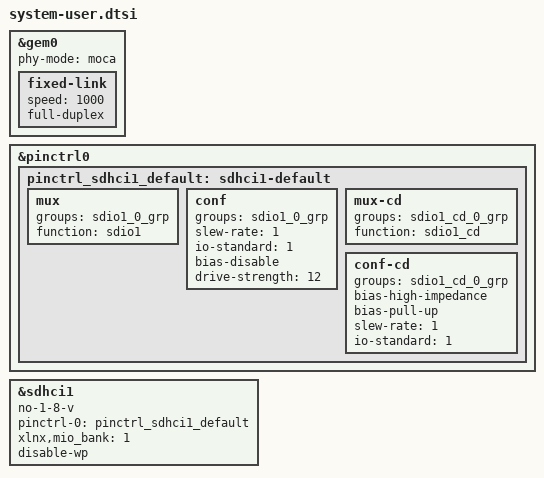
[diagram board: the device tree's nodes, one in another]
/include/ "system-conf.dtsi"
/ {
};




&gem0 {
        phy-mode = "moca";
        fixed-link {
          speed = <1000>;
          full-duplex;
	};
};


&pinctrl0 {
	status = "okay";

      
	pinctrl_sdhci1_default: sdhci1-default {
		mux {
			groups = "sdio1_0_grp";
			function = "sdio1";
		};

		conf {
			groups = "sdio1_0_grp";
			slew-rate = <1>;
			io-standard = <1>;
			bias-disable;
			drive-strength = <12>;
		};

		mux-cd {
			groups = "sdio1_cd_0_grp";
			function = "sdio1_cd";
		};

		conf-cd {
			groups = "sdio1_cd_0_grp";
			bias-high-impedance;
			bias-pull-up;
			slew-rate = <1>;
			io-standard = <1>;
		};
	};

};



/* SD1 with level shifter */
&sdhci1 {
	no-1-8-v;
	pinctrl-names = "default";
	pinctrl-0 = <&pinctrl_sdhci1_default>;
	xlnx,mio_bank = <1>;
	disable-wp;
};
